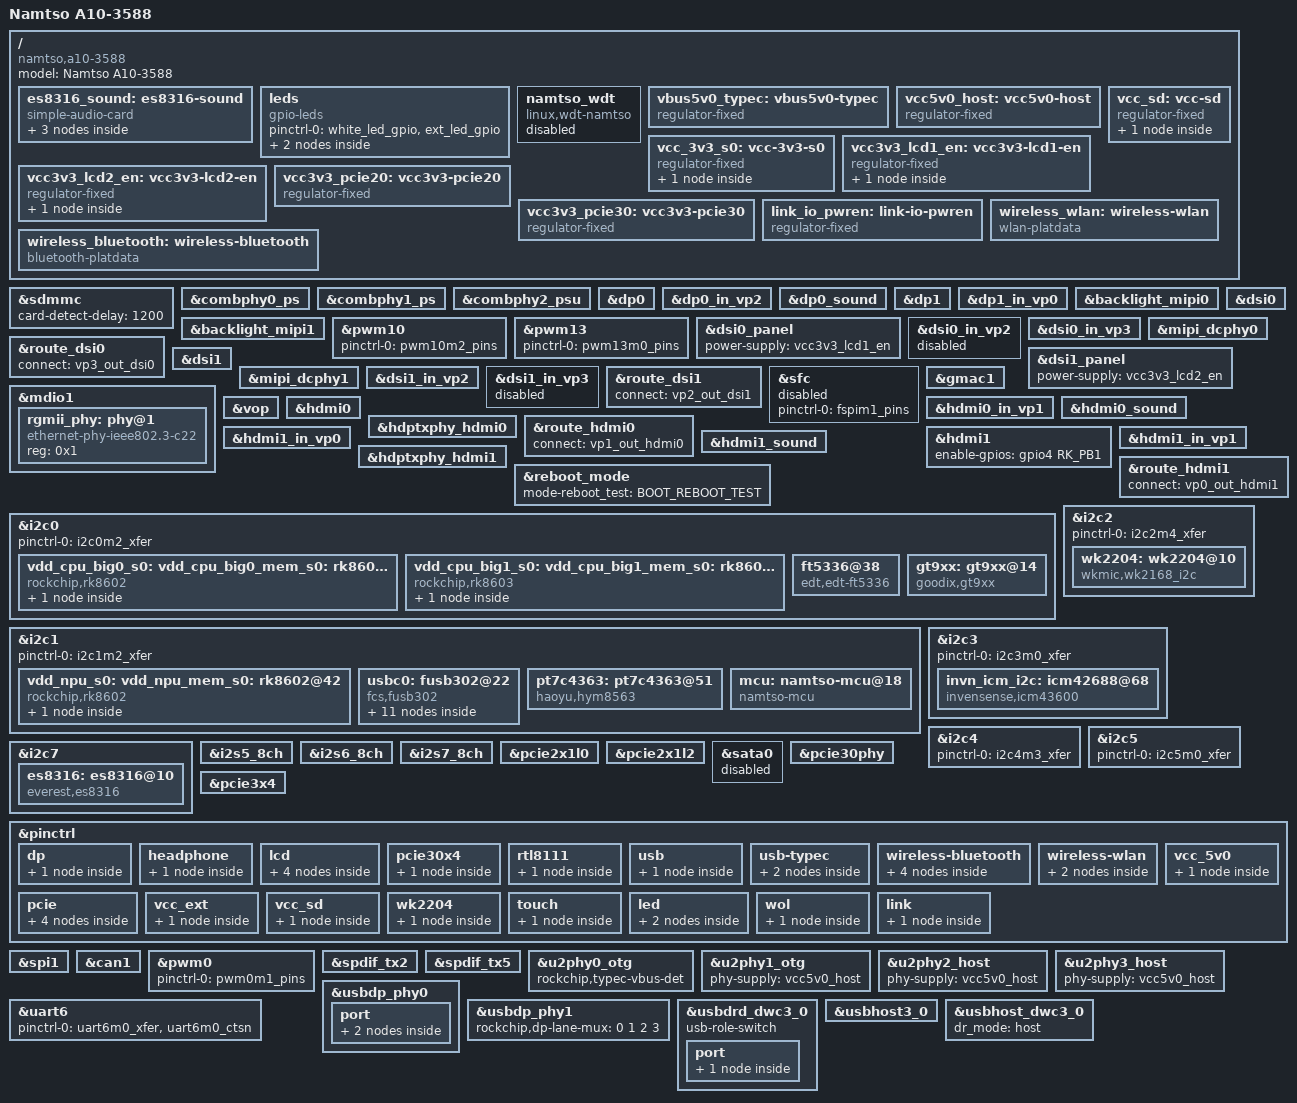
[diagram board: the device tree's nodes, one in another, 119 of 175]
// SPDX-License-Identifier: (GPL-2.0+ OR MIT)
/*
 * Copyright (c) 2023 Namtso Technology Co., Ltd.
 *
 */

/dts-v1/;

#include "dt-bindings/usb/pd.h"
#include "rk3588.dtsi"
#include "rk3588-rk806-single.dtsi"
#include "rk3588-linux.dtsi"
#include "rk3588-namtso-a10-3588.dtsi"
#include "rk3588-namtso-a10-3588-camera.dtsi"

/ {
    model = "Namtso A10-3588";
    compatible = "namtso,a10-3588", "rockchip,rk3588";

	es8316_sound: es8316-sound {
		compatible = "simple-audio-card";
		simple-audio-card,format = "i2s";
		simple-audio-card,mclk-fs = <256>;
		simple-audio-card,name = "rockchip,es8316-codec";
		simple-audio-card,dai-link@0 {
			format = "i2s";
			cpu {
				sound-dai = <&i2s0_8ch>;
			};
			codec {
				sound-dai = <&es8316>;
			};
 		};
 	};

	leds {
		compatible = "gpio-leds";
		pinctrl-names = "default";
		pinctrl-0 = <&white_led_gpio &ext_led_gpio>;

		white_led {
			gpios = <&gpio0 RK_PC7 GPIO_ACTIVE_HIGH>;
			label = "white_led";
			linux,default-trigger = "none";
			default-state = "on";
		};

		ext_led {
			gpios = <&gpio0 RK_PD0 GPIO_ACTIVE_HIGH>;
			label = "ext_led";
			linux,default-trigger = "none";
			default-state = "on";
		};
	};

	namtso_wdt {
		compatible = "linux,wdt-namtso";
		status = "disabled";
		hw_margin_ms = <500>;
		hw-gpios = <&gpio0 RK_PB0 GPIO_ACTIVE_HIGH>;
	};

	vbus5v0_typec: vbus5v0-typec {
		compatible = "regulator-fixed";
		regulator-name = "vbus5v0_typec";
		regulator-min-microvolt = <5000000>;
		regulator-max-microvolt = <5000000>;
		enable-active-high;
		gpio = <&gpio2 RK_PB6 GPIO_ACTIVE_HIGH>;
		vin-supply = <&vcc_5v0>;
		pinctrl-names = "default";
		pinctrl-0 = <&typec5v_pwren>;
	};

	vcc5v0_host: vcc5v0-host {
		compatible = "regulator-fixed";
		regulator-name = "vcc5v0_host";
		regulator-boot-on;
		regulator-always-on;
		regulator-min-microvolt = <5000000>;
		regulator-max-microvolt = <5000000>;
		enable-active-high;
		gpio = <&gpio2 RK_PB2 GPIO_ACTIVE_HIGH>;
		vin-supply = <&vcc_5v0>;
		pinctrl-names = "default";
		pinctrl-0 = <&vcc5v0_host_en>;
	};

	vcc_3v3_s0: vcc-3v3-s0 {
		compatible = "regulator-fixed";
		regulator-name = "vcc_3v3_s0";
		regulator-always-on;
		regulator-boot-on;
		regulator-min-microvolt = <3300000>;
		regulator-max-microvolt = <3300000>;
		vin-supply = <&vcc_3v3_s3>;
		regulator-state-mem {
			regulator-on-in-suspend;
		};
	};

	vcc_sd: vcc-sd {
		compatible = "regulator-fixed";
		regulator-name = "vcc_sd";
		regulator-boot-on;
		regulator-always-on;
		regulator-min-microvolt = <3300000>;
		regulator-max-microvolt = <3300000>;
		enable-active-low;
		gpio = <&gpio3 RK_PB2 GPIO_ACTIVE_LOW>;
		vin-supply = <&vcc_3v3_s3>;
		pinctrl-names = "default";
		pinctrl-0 = <&vcc_sd_en>;
		regulator-state-mem {
			regulator-off-in-suspend;
		};
	};

	vcc3v3_lcd1_en: vcc3v3-lcd1-en {
		compatible = "regulator-fixed";
		regulator-name = "vcc3v3_lcd1_en";
		regulator-min-microvolt = <3300000>;
		regulator-max-microvolt = <3300000>;
		gpio = <&gpio3 RK_PC0 GPIO_ACTIVE_HIGH>;
		enable-active-high;
		regulator-boot-on;
		regulator-state-mem {
			regulator-off-in-suspend;
		};
    };

    vcc3v3_lcd2_en: vcc3v3-lcd2-en {
		compatible = "regulator-fixed";
		regulator-name = "vcc3v3_lcd2_en";
		regulator-min-microvolt = <3300000>;
		regulator-max-microvolt = <3300000>;
		gpio = <&gpio3 RK_PD2 GPIO_ACTIVE_HIGH>;
		enable-active-high;
		regulator-boot-on;
		regulator-state-mem {
			regulator-off-in-suspend;
		};
    };

	vcc3v3_pcie20: vcc3v3-pcie20 {
		compatible = "regulator-fixed";
		regulator-name = "vcc3v3_pcie20";
		regulator-min-microvolt = <3300000>;
		regulator-max-microvolt = <3300000>;
		gpios = <&gpio0 RK_PC4 GPIO_ACTIVE_HIGH>;
		enable-active-high;
		regulator-boot-on;
		startup-delay-us = <5000>;
	};

	vcc3v3_pcie30: vcc3v3-pcie30 {
		compatible = "regulator-fixed";
		regulator-name = "vcc3v3_pcie30";
		regulator-min-microvolt = <3300000>;
		regulator-max-microvolt = <3300000>;
		gpios = <&gpio2 RK_PC5 GPIO_ACTIVE_HIGH>;
		pinctrl-names = "default";
		pinctrl-0 = <&vcc3vc_clken_gpio>;
		enable-active-high;
		regulator-boot-on;
		regulator-always-on;
		startup-delay-us = <5000>;
		vin-supply = <&vcc4v0_sys>;
	};

	link_io_pwren: link-io-pwren {
		compatible = "regulator-fixed";
		regulator-name = "link_io_pwren";
		regulator-boot-on;
		regulator-always-on;
		enable-active-high;
		gpio = <&gpio4 RK_PA0 GPIO_ACTIVE_HIGH>;
		vin-supply = <&vcc_1v8_s0>;
		pinctrl-names = "default";
		pinctrl-0 = <&link_io_pwren_gpio>;
	};

	wireless_bluetooth: wireless-bluetooth {
		compatible = "bluetooth-platdata";
		clocks = <&pt7c4363>;
		clock-names = "ext_clock";
		uart_rts_gpios = <&gpio2 RK_PB0 GPIO_ACTIVE_LOW>;
		pinctrl-names = "default", "rts_gpio";
		pinctrl-0 = <&uart6m0_rtsn>, <&bt_reset_gpio>, <&bt_wake_gpio>, <&bt_irq_gpio>;
		pinctrl-1 = <&uart6_gpios>;
		BT,reset_gpio    = <&gpio0 RK_PC6 GPIO_ACTIVE_HIGH>;
		BT,wake_gpio     = <&gpio0 RK_PC5 GPIO_ACTIVE_HIGH>;
		BT,wake_host_irq = <&gpio0 RK_PA0 GPIO_ACTIVE_HIGH>;
		status = "okay";
	};

	wireless_wlan: wireless-wlan {
		compatible = "wlan-platdata";
		wifi_chip_type = "ap6275p";
		pinctrl-names = "default";
		pinctrl-0 = <&wifi_host_wake_irq>, <&wifi_poweren_gpio>;
		WIFI,host_wake_irq = <&gpio0 RK_PB2 GPIO_ACTIVE_HIGH>;
		//WIFI,poweren_gpio = <&gpio0 RK_PC4 GPIO_ACTIVE_HIGH>;
		status = "okay";
	};
};

&sdmmc {
	status = "okay";
	card-detect-delay = <1200>;
};

/* pcie2x1l2 */
&combphy0_ps {
	status = "okay";
};

/* pcie2x1l0 */
&combphy1_ps {
	status = "okay";
};

/* pcie2x1l1 */
&combphy2_psu {
	status = "okay";
};

&dp0 {
	status = "okay";
};

&dp0_in_vp2 {
	status = "okay";
};

&dp0_sound{
	status = "okay";
};

&dp1 {
	pinctrl-names = "default";
	pinctrl-0 = <&dp1_hpd>;
	hpd-gpios = <&gpio3 RK_PD5 GPIO_ACTIVE_HIGH>;
	status = "okay";
};

&dp1_in_vp0 {
	status = "okay";
};

&backlight_mipi0 {
	pwms = <&pwm13 0 25000 0>;
	power-supply = <&vcc3v3_lcd1_en>;
	status = "okay";
};

&backlight_mipi1 {
	pwms = <&pwm10 0 25000 0>;
	power-supply = <&vcc3v3_lcd2_en>;
	status = "okay";
};

&pwm10 {
	pinctrl-0 = <&pwm10m2_pins>;
	status = "okay";
};

&pwm13 {
	pinctrl-0 = <&pwm13m0_pins>;
	status = "okay";
};

/*
 * mipi_dcphy0 needs to be enabled
 * when dsi0 is enabled
 */
&dsi0 {
	status = "okay";
	reset-delay-ms = <20>;
	reset-gpios = <&gpio3 RK_PC1 GPIO_ACTIVE_HIGH>;
	pinctrl-names = "default";
	pinctrl-0 = <&lcd1_rst_gpio>;
};

&dsi0_panel {
	status = "okay";
	power-supply = <&vcc3v3_lcd1_en>;
};

&dsi0_in_vp2 {
	status = "disabled";
};

&dsi0_in_vp3 {
	status = "okay";
};

&route_dsi0 {
	status = "okay";
	connect = <&vp3_out_dsi0>;
};

&mipi_dcphy0 {
	status = "okay";
};

&dsi1 {
	reset-delay-ms = <20>;
	reset-gpios = <&gpio3 RK_PD4 GPIO_ACTIVE_HIGH>;
	pinctrl-names = "default";
	pinctrl-0 = <&lcd2_rst_gpio>;
	status = "okay";
};

&dsi1_panel {
	status = "okay";
	power-supply = <&vcc3v3_lcd2_en>;
};

&mipi_dcphy1 {
	status = "okay";
};

&dsi1_in_vp2 {
	status = "okay";
};

&dsi1_in_vp3 {
	status = "disabled";
};

&route_dsi1 {
	status = "okay";
	connect = <&vp2_out_dsi1>;
};

&sfc {
	status = "disabled";
	pinctrl-names = "default";
	pinctrl-0 = <&fspim1_pins>;
};

&gmac1 {
	/* Use rgmii-rxid mode to disable rx delay inside Soc */
	phy-mode = "rgmii-rxid";
	clock_in_out = "output";

	snps,reset-gpio = <&gpio3 RK_PB7 GPIO_ACTIVE_HIGH>;
	snps,reset-active-low;
	/* Reset time is 20ms, 100ms for rtl8211f */
	snps,reset-delays-us = <0 20000 100000>;

	wolirq-gpio = <&gpio0 RK_PC2 GPIO_ACTIVE_LOW>;
	wolctrl-gpio = <&gpio4 RK_PC4 GPIO_ACTIVE_LOW>;

	pinctrl-names = "default";
	pinctrl-0 = <&gmac1_miim
		     &gmac1_tx_bus2
		     &gmac1_rx_bus2
		     &gmac1_rgmii_clk
		     &gmac1_rgmii_bus
			 &wol_gpio>;

	tx_delay = <0x39>;
	/* rx_delay = <0x3f>; */

	phy-handle = <&rgmii_phy>;
	status = "okay";
};

&mdio1 {
	rgmii_phy: phy@1 {
		compatible = "ethernet-phy-ieee802.3-c22";
		reg = <0x1>;
	};
};

&vop {
	assigned-clocks = <&cru ACLK_VOP>;
	assigned-clock-rates = <800000000>;
};

&hdmi0 {
	status = "okay";
};

&hdmi0_in_vp1 {
	status = "okay";
};

&hdmi0_sound {
	status = "okay";
};

&hdptxphy_hdmi0 {
	status = "okay";
};

&route_hdmi0 {
	status = "okay";
	connect = <&vp1_out_hdmi0>;
};

&hdmi1 {
	enable-gpios = <&gpio4 RK_PB1 GPIO_ACTIVE_HIGH>;
	status = "okay";
};

&hdmi1_in_vp0 {
	status = "okay";
};

&hdmi1_in_vp1 {
	status = "okay";
};

&hdmi1_sound {
	status = "okay";
};

&hdptxphy_hdmi1 {
	status = "okay";
};

&route_hdmi1 {
	status = "okay";
	connect = <&vp0_out_hdmi1>;
};

&reboot_mode {
	mode-reboot_test = <BOOT_REBOOT_TEST>;
};

&i2c0 {
    status = "okay";

    pinctrl-names = "default";
    pinctrl-0 = <&i2c0m2_xfer>;

    vdd_cpu_big0_s0: vdd_cpu_big0_mem_s0: rk8602@42 {
        compatible = "rockchip,rk8602";
        reg = <0x42>;
        vin-supply = <&vcc4v0_sys>;
        regulator-compatible = "rk860x-reg";
        regulator-name = "vdd_cpu_big0_s0";
        regulator-min-microvolt = <550000>;
        regulator-max-microvolt = <1050000>;
        regulator-ramp-delay = <12500>;
        rockchip,suspend-voltage-selector = <1>;
        regulator-boot-on;
        regulator-always-on;
        regulator-state-mem {
            regulator-off-in-suspend;
        };
    };

    vdd_cpu_big1_s0: vdd_cpu_big1_mem_s0: rk8603@43 {
        compatible = "rockchip,rk8603";
        reg = <0x43>;
        vin-supply = <&vcc4v0_sys>;
        regulator-compatible = "rk860x-reg";
        regulator-name = "vdd_cpu_big1_s0";
        regulator-min-microvolt = <550000>;
        regulator-max-microvolt = <1050000>;
        regulator-ramp-delay = <12500>;
        rockchip,suspend-voltage-selector = <1>;
        regulator-boot-on;
        regulator-always-on;
        regulator-state-mem {
            regulator-off-in-suspend;
        };
	};

	ft5336@38 {
		compatible = "edt,edt-ft5336", "ft5x06";
		reg = <0x38>;
		interrupt-parent = <&gpio0>;
		interrupts = <RK_PB7 IRQ_TYPE_EDGE_FALLING>;
		reset-gpio = <&gpio0 RK_PC0 GPIO_ACTIVE_HIGH>;
		pinctrl-names = "default";
		pinctrl-0 = <&tp_rst_gpio>;
		status = "okay";
	};

	gt9xx: gt9xx@14 {
		compatible = "goodix,gt9xx";
		reg = <0x14>;
		touch-gpio = <&gpio0 RK_PB7 IRQ_TYPE_LEVEL_LOW>;
		reset-gpio = <&gpio0 RK_PC0 GPIO_ACTIVE_HIGH>;
		max-x = <1920>;
		max-y = <1200>;
		tp-size = <89>;
	};
};

&i2c1 {
	status = "okay";

	pinctrl-names = "default";
	pinctrl-0 = <&i2c1m2_xfer>;

	vdd_npu_s0: vdd_npu_mem_s0: rk8602@42 {
		compatible = "rockchip,rk8602";
		reg = <0x42>;
		vin-supply = <&vcc4v0_sys>;
		regulator-compatible = "rk860x-reg";
		regulator-name = "vdd_npu_s0";
		regulator-min-microvolt = <550000>;
		regulator-max-microvolt = <950000>;
		regulator-ramp-delay = <12500>;
		rockchip,suspend-voltage-selector = <1>;
		regulator-boot-on;
		regulator-always-on;
		regulator-state-mem {
			regulator-off-in-suspend;
		};
	};


	usbc0: fusb302@22 {
		compatible = "fcs,fusb302";
		reg = <0x22>;
		interrupt-parent = <&gpio0>;
		interrupts = <RK_PD3 IRQ_TYPE_LEVEL_LOW>;
		int-n-gpios = <&gpio0 RK_PD3 GPIO_ACTIVE_LOW>;
		pinctrl-names = "default";
		pinctrl-0 = <&usbc0_int>;
		vbus-supply = <&vbus5v0_typec>;
		status = "okay";

		ports {
			#address-cells = <1>;
			#size-cells = <0>;

			port@0 {
				reg = <0>;
				usbc0_role_sw: endpoint@0 {
					remote-endpoint = <&dwc3_0_role_switch>;
				};
			};
		};

		usb_con: connector {
			compatible = "usb-c-connector";
			label = "USB-C";
			data-role = "dual";
			power-role = "dual";
			try-power-role = "sink";
			op-sink-microwatt = <1000000>;
			sink-pdos =
				 <PDO_FIXED(5000, 3000, PDO_FIXED_USB_COMM)
				 PDO_FIXED(9000, 3000, PDO_FIXED_USB_COMM)
				 PDO_FIXED(12000, 3000, PDO_FIXED_USB_COMM)>;
			source-pdos =
				<PDO_FIXED(5000, 3000, PDO_FIXED_USB_COMM)>;

			altmodes {
				#address-cells = <1>;
				#size-cells = <0>;

				altmode@0 {
					reg = <0>;
					svid = <0xff01>;
					vdo = <0xffffffff>;
				};
			};

			ports {
				#address-cells = <1>;
				#size-cells = <0>;

				port@0 {
					reg = <0>;
					usbc0_orien_sw: endpoint {
						remote-endpoint = <&usbdp_phy0_orientation_switch>;
					};
				};

				port@1 {
					reg = <1>;
					dp_altmode_mux: endpoint {
						remote-endpoint = <&usbdp_phy0_dp_altmode_mux>;
					};
				};
			};
		};
	};

	pt7c4363: pt7c4363@51 {
		compatible = "haoyu,hym8563";
		reg = <0x51>;
		#clock-cells = <0>;
		clock-frequency = <32768>;
		clock-output-names = "pt7c4363";
		wakeup-source;
	};

	mcu: namtso-mcu@18 {
		compatible = "namtso-mcu";
		status = "okay";
		reg = <0x18>;
		fan,trig_temp_level0 = <50>;
		fan,trig_temp_level1 = <60>;
		fan,trig_temp_level2 = <70>;
		fan,trig_temp_level3 = <80>;
	};
};

&i2c2 {
	status = "okay";

	pinctrl-names = "default";
	pinctrl-0 = <&i2c2m4_xfer>;

	wk2204: wk2204@10 {
		compatible = "wkmic,wk2168_i2c";
		reg = <0x10>;
		irq_gpio = <&gpio1 RK_PA7 GPIO_ACTIVE_HIGH>;
		pinctrl-names = "default";
		pinctrl-0 = <&wk2204_irq_gpio>;
	};
};

&i2c3 {
	status = "okay";
	pinctrl-names = "default";
	pinctrl-0 = <&i2c3m0_xfer>;

	invn_icm_i2c: icm42688@68 {
		status = "okay";
		compatible = "invensense,icm43600";
		reg = <0x68>;
		interrupt-parent = <&gpio1>;
		interrupts = <RK_PD5 GPIO_ACTIVE_HIGH>;
		axis_map_x = <1>;
		axis_map_y = <0>;
		axis_map_z = <2>;
		negate_x = <1>;
		negate_y = <0>;
		negate_z = <0>;
		inven,secondary_type = "none";
		inven,aux_type = "none";
		inven,read_only_slave_type = "none";
	};
};

&i2c4 {
	pinctrl-names = "default";
	pinctrl-0 = <&i2c4m3_xfer>;
	status = "okay";
};

&i2c5 {
	pinctrl-names = "default";
	pinctrl-0 = <&i2c5m0_xfer>;
	status = "okay";
};

&i2c7 {
	status = "okay";

	es8316: es8316@10 {
		status = "okay";
		#sound-dai-cells = <0>;
		compatible = "everest,es8316";
		reg = <0x10>;
		clocks = <&cru I2S0_8CH_MCLKOUT>;
		clock-names = "mclk";
		assigned-clocks = <&mclkout_i2s0>;
		assigned-clock-rates = <12288000>;
		pinctrl-names = "default","hp_det","spk_con";
		pinctrl-0 = <&i2s0_mclk>,<&hp_det>;//<&spk_con>;
		//spk-con-gpio = <&gpio1 RK_PD0 GPIO_ACTIVE_HIGH>;
		hp-det-gpio = <&gpio1 RK_PC4 GPIO_ACTIVE_HIGH>;
	};
};

&i2s5_8ch {
	status = "okay";
};

&i2s6_8ch {
	status = "okay";
};

&i2s7_8ch {
	status = "okay";
};

&mipi_dcphy0 {
	status = "okay";
};

&mipi_dcphy1 {
	status = "okay";
};

&pcie2x1l0 {
	reset-gpios = <&gpio1 RK_PB4 GPIO_ACTIVE_HIGH>;
	vpcie3v3-supply = <&vcc3v3_pcie20>;
	pinctrl-names = "default";
	pinctrl-0 = <&pcie2x1l0_gpio>;
	rockchip,skip-scan-in-resume;
	rockchip,perst-inactive-ms = <500>;
	status = "okay";
};

&pcie2x1l2 {
	reset-gpios = <&gpio3 RK_PD1 GPIO_ACTIVE_HIGH>;
	pinctrl-names = "default";
	pinctrl-0 = <&pcie2x1l1_gpio>;
	rockchip,skip-scan-in-resume;
	status = "okay";
};

&sata0 {
	status = "disabled";
};

&pcie30phy {
	rockchip,pcie30-phymode = <PHY_MODE_PCIE_AGGREGATION>;
	status = "okay";
};

&pcie3x4 {
	reset-gpios = <&gpio4 RK_PB6 GPIO_ACTIVE_HIGH>;
	vpcie3v3-supply = <&vcc3v3_pcie30>;
	pinctrl-names = "default";
	pinctrl-0 = <&pcie3x4_gpio>;
	status = "okay";
};

&pinctrl {
	dp {
		dp1_hpd: dp1-hpd {
			rockchip,pins = <1 RK_PB5 RK_FUNC_GPIO &pcfg_pull_none>;
		};
	};

	headphone {
		hp_det: hp-det {
			rockchip,pins = <1 RK_PC4 RK_FUNC_GPIO &pcfg_pull_none>;
		};
	};

	lcd {
		lcd1_rst_gpio: lcd1-rst-gpio {
			rockchip,pins = <3 RK_PC1 RK_FUNC_GPIO &pcfg_pull_none>;
		};

		lcd1_enable_gpio: lcd1-enable-gpio {
			rockchip,pins = <3 RK_PC0 RK_FUNC_GPIO &pcfg_pull_none>;
		};

		lcd2_rst_gpio: lcd2-rst-gpio {
			rockchip,pins = <3 RK_PD4 RK_FUNC_GPIO &pcfg_pull_none>;
		};

		lcd2_enable_gpio: lcd2-enable-gpio {
			rockchip,pins = <3 RK_PD2 RK_FUNC_GPIO &pcfg_pull_none>;
		};
	};

	pcie30x4 {
		pcie30x4_clkreqn_m1: pcie30x4-clkreqn-m1 {
			rockchip,pins = <4 RK_PB4 RK_FUNC_GPIO &pcfg_pull_down>;
		};
	};

	rtl8111 {
		rtl8111_isolate: rtl8111-isolate {
			rockchip,pins = <1 RK_PA4 RK_FUNC_GPIO &pcfg_pull_up>;
		};
	};

	usb {
		vcc5v0_host_en: vcc5v0-host-en {
			rockchip,pins = <2 RK_PB2 RK_FUNC_GPIO &pcfg_pull_none>;
		};
	};

	usb-typec {
		usbc0_int: usbc0-int {
			rockchip,pins = <0 RK_PD3 RK_FUNC_GPIO &pcfg_pull_up>;
		};

		typec5v_pwren: typec5v-pwren {
			rockchip,pins = <2 RK_PB6 RK_FUNC_GPIO &pcfg_pull_none>;
		};
	};

	wireless-bluetooth {
		uart6_gpios: uart6-gpios {
			rockchip,pins = <2 RK_PB0 RK_FUNC_GPIO &pcfg_pull_none>;
		};

		bt_reset_gpio: bt-reset-gpio {
			rockchip,pins = <0 RK_PC6 RK_FUNC_GPIO &pcfg_pull_none>;
		};

		bt_wake_gpio: bt-wake-gpio {
			rockchip,pins = <0 RK_PC5 RK_FUNC_GPIO &pcfg_pull_none>;
		};

		bt_irq_gpio: bt-irq-gpio {
			rockchip,pins = <0 RK_PA0 RK_FUNC_GPIO &pcfg_pull_down>;
		};
	};

	wireless-wlan {
		wifi_host_wake_irq: wifi-host-wake-irq {
			rockchip,pins = <0 RK_PB2 RK_FUNC_GPIO &pcfg_pull_down>;
		};

		wifi_poweren_gpio: wifi-poweren-gpio {
			rockchip,pins = <0 RK_PC4 RK_FUNC_GPIO &pcfg_pull_up>;
		};
	};
	pcie {
		pcie2x1l0_gpio: pcie2x1l0-gpio {
			rockchip,pins = <3 RK_PD1 RK_FUNC_GPIO &pcfg_pull_down>;
		};

		pcie2x1l1_gpio: pcie2x1l1-gpio {
			rockchip,pins = <1 RK_PB4 RK_FUNC_GPIO &pcfg_pull_down>;
		};
		pcie3x4_gpio: pcie3x4-gpio {
			rockchip,pins = <4 RK_PB6 RK_FUNC_GPIO &pcfg_pull_down>;
		};

		vcc3vc_clken_gpio: vcc3vc-clken-gpio {
			rockchip,pins = <2 RK_PC5 RK_FUNC_GPIO &pcfg_pull_down>;
		};
	};
	vcc_5v0 {
		vcc5v0_en: vcc5v0-en {
			rockchip,pins = <2 RK_PB3 RK_FUNC_GPIO &pcfg_pull_none>;
		};
	};

	vcc_ext {
		vcc_3v3_ext_en: vcc-3v3-ext-en {
			rockchip,pins = <0 RK_PC2 RK_FUNC_GPIO &pcfg_pull_none>;
		};
	};

	vcc_sd {
		vcc_sd_en: vcc-sd-en {
			rockchip,pins = <3 RK_PB2 RK_FUNC_GPIO &pcfg_pull_up>;
		};
	};

	wk2204 {
		wk2204_irq_gpio: wk2204-irq-gpio {
			rockchip,pins = <1 RK_PA7 RK_FUNC_GPIO &pcfg_pull_none>;
		};
	};

	touch {
		tp_rst_gpio: tp-rst-gpio {
			rockchip,pins = <0 RK_PC0 RK_FUNC_GPIO &pcfg_pull_none>;
		};
	};

	led {
		white_led_gpio: white-led-gpio {
			rockchip,pins = <0 RK_PC7 RK_FUNC_GPIO &pcfg_pull_none>;
		};
		ext_led_gpio: ext-led-gpio {
			rockchip,pins = <0 RK_PD0 RK_FUNC_GPIO &pcfg_pull_none>;
		};
	};

	wol {
		wol_gpio: wol-gpio {
			rockchip,pins = <0 RK_PC2 RK_FUNC_GPIO &pcfg_pull_up>;
		};
	};

	link {
		link_io_pwren_gpio: link-io-pwren-gpio {
			rockchip,pins = <4 RK_PA0 RK_FUNC_GPIO &pcfg_pull_none>;
		};
	};
};

&spi1 {
	pinctrl-names = "default";
	pinctrl-0 = <&spi1m0_cs0 &spi1m0_pins>;
	num-cs = <1>;
	status = "okay";
};

&can1 {
        status = "okay";
        assigned-clocks = <&cru CLK_CAN1>;
        assigned-clock-rates = <200000000>;
        pinctrl-names = "default";
        pinctrl-0 = <&can1m1_pins>;
};

&pwm0 {
	pinctrl-0 = <&pwm0m1_pins>;
	status = "okay";
};

/* hdmi0_sound */
&i2s5_8ch {
	status = "okay";
};

/* hdmi1_sound */
&i2s6_8ch {
	status = "okay";
};

/* dp0_sound */
&spdif_tx2 {
	status = "okay";
};
/* dp1_sound */
&spdif_tx5 {
	status = "okay";
};

&u2phy0_otg {
	rockchip,typec-vbus-det;
};

&u2phy1_otg {
	phy-supply = <&vcc5v0_host>;
};

&u2phy2_host {
	phy-supply = <&vcc5v0_host>;
};

&u2phy3_host {
	phy-supply = <&vcc5v0_host>;
};

&uart6 {
	status = "okay";
	pinctrl-names = "default";
	pinctrl-0 = <&uart6m0_xfer &uart6m0_ctsn>;
};

&usbdp_phy0 {
	orientation-switch;
	svid = <0xff01>;
	sbu1-dc-gpios = <&gpio4 RK_PA6 GPIO_ACTIVE_HIGH>;
	sbu2-dc-gpios = <&gpio4 RK_PA7 GPIO_ACTIVE_HIGH>;

	port {
		#address-cells = <1>;
		#size-cells = <0>;
		usbdp_phy0_orientation_switch: endpoint@0 {
			reg = <0>;
			remote-endpoint = <&usbc0_orien_sw>;
		};

		usbdp_phy0_dp_altmode_mux: endpoint@1 {
			reg = <1>;
			remote-endpoint = <&dp_altmode_mux>;
		};
	};
};

&usbdp_phy1 {
	rockchip,dp-lane-mux = <0 1 2 3>;
};

&usbdrd_dwc3_0 {
	usb-role-switch;
	port {
		#address-cells = <1>;
		#size-cells = <0>;
		dwc3_0_role_switch: endpoint@0 {
			reg = <0>;
			remote-endpoint = <&usbc0_role_sw>;
		};
	};
};

&usbhost3_0 {
	status = "okay";
};

&usbhost_dwc3_0 {
	dr_mode = "host";
	status = "okay";
};


